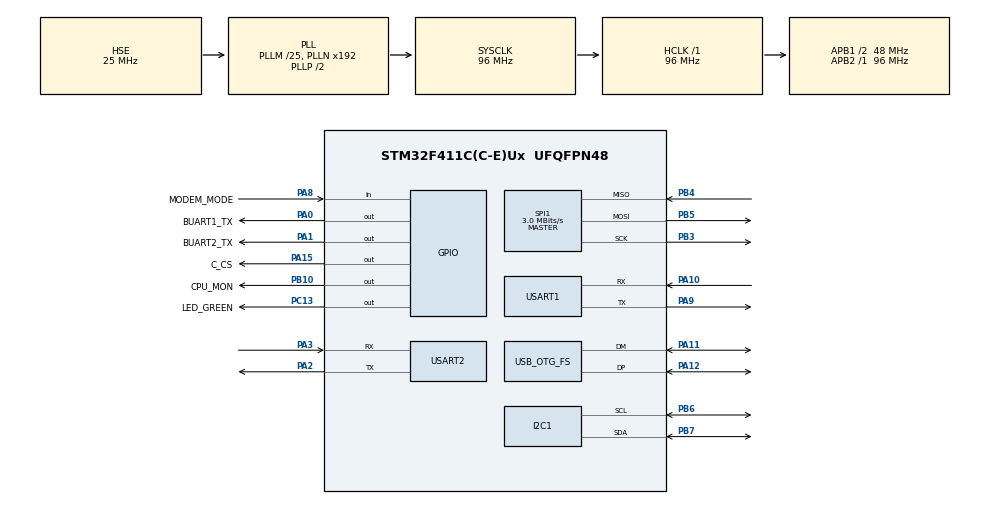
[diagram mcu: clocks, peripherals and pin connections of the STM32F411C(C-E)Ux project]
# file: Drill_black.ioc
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FREERTOS.Queues01=QueueTX,4,HdlcFrame_t,0,Static,QueueTXBuffer,QueueTXControlBlock;QueueRX,4,HdlcFrame_t,0,Static,QueueRXBuffer,QueueRXControlBlock
FREERTOS.Tasks01=defaultTask,24,256,StartDefaultTask,Default,NULL,Static,defaultTaskBuffer,defaultTaskControlBlock;TaskHDLC,48,256,StartTaskHDLC,As weak,NULL,Static,TaskHDLCBuffer,TaskHDLCControlBlock;TaskHK,8,256,StartTaskHK,As weak,NULL,Static,TaskHKBuffer,TaskHKControlBlock
Mcu.Family=STM32F4
Mcu.Name=STM32F411C(C-E)Ux
Mcu.Package=UFQFPN48
NVIC.OTG_FS_IRQn=true\:5\:0\:false\:false\:true\:true\:false\:true\:true
NVIC.PriorityGroup=NVIC_PRIORITYGROUP_4
NVIC.TIM2_IRQn=true\:5\:0\:false\:false\:true\:true\:true\:true\:true
NVIC.TIM3_IRQn=true\:5\:0\:false\:false\:true\:true\:true\:true\:true
NVIC.TIM5_IRQn=true\:15\:0\:false\:false\:true\:false\:false\:true\:true
NVIC.TimeBase=TIM5_IRQn
NVIC.TimeBaseIP=TIM5
PA0-WKUP.GPIO_Label=BUART1_TX
PA0-WKUP.Signal=GPIO_Output
PA1.GPIO_Label=BUART2_TX
PA1.Signal=GPIO_Output
PA10.Mode=Asynchronous
PA10.Signal=USART1_RX
PA11.Mode=Host_Only
PA11.Signal=USB_OTG_FS_DM
PA12.Mode=Host_Only
PA12.Signal=USB_OTG_FS_DP
PA13.Mode=Serial_Wire
PA13.Signal=SYS_JTMS-SWDIO
PA14.Mode=Serial_Wire
PA14.Signal=SYS_JTCK-SWCLK
PA15.GPIO_Label=C_CS
PA15.Signal=GPIO_Output
PA2.Mode=Asynchronous
PA2.Signal=USART2_TX
PA3.Mode=Asynchronous
PA3.Signal=USART2_RX
PA8.GPIO_Label=MODEM_MODE
PA8.GPIO_PuPd=GPIO_PULLUP
PA8.Signal=GPIO_Input
PA9.Mode=Asynchronous
PA9.Signal=USART1_TX
PB10.GPIO_Label=CPU_MON
PB10.Signal=GPIO_Output
PB3.Mode=Full_Duplex_Master
PB3.Signal=SPI1_SCK
PB4.Mode=Full_Duplex_Master
PB4.Signal=SPI1_MISO
PB5.Mode=Full_Duplex_Master
PB5.Signal=SPI1_MOSI
PB6.Mode=I2C
PB6.Signal=I2C1_SCL
PB7.Mode=I2C
PB7.Signal=I2C1_SDA
PC13-ANTI_TAMP.GPIO_Label=LED_GREEN
PC13-ANTI_TAMP.Signal=GPIO_Output
PC14-OSC32_IN.Mode=LSE-External-Oscillator
PC14-OSC32_IN.Signal=RCC_OSC32_IN
PC15-OSC32_OUT.Mode=LSE-External-Oscillator
PC15-OSC32_OUT.Signal=RCC_OSC32_OUT
PH0\ -\ OSC_IN.Mode=HSE-External-Oscillator
PH0\ -\ OSC_IN.Signal=RCC_OSC_IN
PH1\ -\ OSC_OUT.Mode=HSE-External-Oscillator
PH1\ -\ OSC_OUT.Signal=RCC_OSC_OUT
ProjectManager.HeapSize=0x400
ProjectManager.StackSize=0x400
ProjectManager.TargetToolchain=CMake
RCC.48MHZClocksFreq_Value=48000000
RCC.AHBFreq_Value=96000000
RCC.APB1CLKDivider=RCC_HCLK_DIV2
RCC.APB1Freq_Value=48000000
RCC.APB1TimFreq_Value=96000000
RCC.APB2Freq_Value=96000000
RCC.APB2TimFreq_Value=96000000
RCC.CortexFreq_Value=96000000
RCC.HCLKFreq_Value=96000000
RCC.HSE_VALUE=25000000
RCC.HSI_VALUE=16000000
RCC.PLLM=25
RCC.RCC_RTC_Clock_Source=RCC_RTCCLKSOURCE_LSE
RCC.RCC_RTC_Clock_SourceVirtual=RCC_RTCCLKSOURCE_LSE
RCC.SYSCLKFreq_VALUE=96000000
RCC.SYSCLKSource=RCC_SYSCLKSOURCE_PLLCLK
RCC.VCOOutputFreq_Value=192000000
RTC.Month=RTC_MONTH_NOVEMBER
RTC.Year=27
SPI1.BaudRatePrescaler=SPI_BAUDRATEPRESCALER_32
SPI1.CalculateBaudRate=3.0 MBits/s
SPI1.Direction=SPI_DIRECTION_2LINES
SPI1.Mode=SPI_MODE_MASTER
SPI1.VirtualType=VM_MASTER
TIM2.AutoReloadPreload=TIM_AUTORELOAD_PRELOAD_ENABLE
TIM2.Period=132
TIM2.Prescaler=99
TIM3.AutoReloadPreload=TIM_AUTORELOAD_PRELOAD_ENABLE
TIM3.Period=79
TIM3.Prescaler=999
USART1.VirtualMode=VM_ASYNC
USART2.VirtualMode=VM_ASYNC
USB_HOST.SW_VBUS_DRIVE_CDC_FS=true
USB_HOST.USBH_HandleTypeDef=hUsbHostFS
USB_HOST.VirtualModeFS=Cdc
USB_OTG_FS.VirtualMode=Host_Only
USB_OTG_FS.phy_itface=HCD_PHY_EMBEDDED
VP_FREERTOS_VS_CMSIS_V2.Mode=CMSIS_V2
VP_RTC_VS_RTC_Activate.Mode=RTC_Enabled
VP_RTC_VS_RTC_Calendar.Mode=RTC_Calendar
VP_SYS_VS_tim5.Mode=TIM5
VP_TIM2_VS_ClockSourceINT.Mode=Internal
VP_TIM3_VS_ClockSourceINT.Mode=Internal
VP_USB_HOST_VS_USB_HOST_CDC_FS.Mode=CDC_FS
board=custom

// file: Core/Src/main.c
/* USER CODE BEGIN Header */
/**
  ******************************************************************************
  * @file           : main.c
  * @brief          : Main program body
  ******************************************************************************
  * @attention
  *
  * Copyright (c) 2026 STMicroelectronics.
  * All rights reserved.
  *
  * This software is licensed under terms that can be found in the LICENSE file
  * in the root directory of this software component.
  * If no LICENSE file comes with this software, it is provided AS-IS.
  *
  ******************************************************************************
  */
/* USER CODE END Header */
#include "main.h"
#include "cmsis_os.h"
#include "usb_host.h"

/* USER CODE BEGIN Includes */
#include "rtt_term.h"
#include "TaskHDLC.h"

/* USER CODE END Includes */

typedef StaticTask_t osStaticThreadDef_t;
typedef StaticQueue_t osStaticMessageQDef_t;

I2C_HandleTypeDef hi2c1;

RTC_HandleTypeDef hrtc;

SPI_HandleTypeDef hspi1;

TIM_HandleTypeDef htim2;
TIM_HandleTypeDef htim3;

UART_HandleTypeDef huart1;
UART_HandleTypeDef huart2;

/* Definitions for defaultTask */
osThreadId_t defaultTaskHandle;
uint32_t defaultTaskBuffer[ 256 ];
osStaticThreadDef_t defaultTaskControlBlock;
const osThreadAttr_t defaultTask_attributes = {
  .name = "defaultTask",
  .cb_mem = &defaultTaskControlBlock,
  .cb_size = sizeof(defaultTaskControlBlock),
  .stack_mem = &defaultTaskBuffer[0],
  .stack_size = sizeof(defaultTaskBuffer),
  .priority = (osPriority_t) osPriorityNormal,
};
/* Definitions for TaskHDLC */
osThreadId_t TaskHDLCHandle;
uint32_t TaskHDLCBuffer[ 256 ];
osStaticThreadDef_t TaskHDLCControlBlock;
const osThreadAttr_t TaskHDLC_attributes = {
  .name = "TaskHDLC",
  .cb_mem = &TaskHDLCControlBlock,
  .cb_size = sizeof(TaskHDLCControlBlock),
  .stack_mem = &TaskHDLCBuffer[0],
  .stack_size = sizeof(TaskHDLCBuffer),
  .priority = (osPriority_t) osPriorityRealtime,
};
/* Definitions for TaskHK */
osThreadId_t TaskHKHandle;
uint32_t TaskHKBuffer[ 256 ];
osStaticThreadDef_t TaskHKControlBlock;
const osThreadAttr_t TaskHK_attributes = {
  .name = "TaskHK",
  .cb_mem = &TaskHKControlBlock,
  .cb_size = sizeof(TaskHKControlBlock),
  .stack_mem = &TaskHKBuffer[0],
  .stack_size = sizeof(TaskHKBuffer),
  .priority = (osPriority_t) osPriorityLow,
};
/* Definitions for QueueTX */
osMessageQueueId_t QueueTXHandle;
uint8_t QueueTXBuffer[ 4 * sizeof( HdlcFrame_t ) ];
osStaticMessageQDef_t QueueTXControlBlock;
const osMessageQueueAttr_t QueueTX_attributes = {
  .name = "QueueTX",
  .cb_mem = &QueueTXControlBlock,
  .cb_size = sizeof(QueueTXControlBlock),
  .mq_mem = &QueueTXBuffer,
  .mq_size = sizeof(QueueTXBuffer)
};
/* Definitions for QueueRX */
osMessageQueueId_t QueueRXHandle;
uint8_t QueueRXBuffer[ 4 * sizeof( HdlcFrame_t ) ];
osStaticMessageQDef_t QueueRXControlBlock;
const osMessageQueueAttr_t QueueRX_attributes = {
  .name = "QueueRX",
  .cb_mem = &QueueRXControlBlock,
  .cb_size = sizeof(QueueRXControlBlock),
  .mq_mem = &QueueRXBuffer,
  .mq_size = sizeof(QueueRXBuffer)
};
/* USER CODE BEGIN PV */
int Is_gse = 0;   /* MODEM_MODE(PA8) が 0(GND) のとき 1 */

/* USER CODE END PV */

void SystemClock_Config(void);
static void MX_GPIO_Init(void);
static void MX_I2C1_Init(void);
static void MX_RTC_Init(void);
static void MX_SPI1_Init(void);
static void MX_USART1_UART_Init(void);
static void MX_USART2_UART_Init(void);
static void MX_TIM2_Init(void);
static void MX_TIM3_Init(void);
void StartDefaultTask(void *argument);
void StartTaskHDLC(void *argument);
void StartTaskHK(void *argument);

int main(void)
{

  /* MCU Configuration--------------------------------------------------------*/

  /* Reset of all peripherals, Initializes the Flash interface and the Systick. */
  HAL_Init();

  /* Configure the system clock */
  SystemClock_Config();

  /* Initialize all configured peripherals */
  MX_GPIO_Init();
  MX_I2C1_Init();
  MX_RTC_Init();
  MX_SPI1_Init();
  MX_USART1_UART_Init();
  MX_USART2_UART_Init();
  MX_TIM2_Init();
  MX_TIM3_Init();
  /* USER CODE BEGIN 2 */
  Is_gse = (HAL_GPIO_ReadPin(MODEM_MODE_GPIO_Port, MODEM_MODE_Pin) == GPIO_PIN_RESET) ? 1 : 0;
  /* TIM2 は StartTaskHDLC() 内で cmx869b_init() 後に開始する */
  /* USER CODE END 2 */

  /* Init scheduler */
  osKernelInitialize();

  /* USER CODE BEGIN RTOS_MUTEX */
  /* add mutexes, ... */
  RTT_TermInit();
  /* USER CODE END RTOS_MUTEX */

  /* Create the queue(s) */
  /* creation of QueueTX */
  QueueTXHandle = osMessageQueueNew (4, sizeof(HdlcFrame_t), &QueueTX_attributes);

  /* creation of QueueRX */
  QueueRXHandle = osMessageQueueNew (4, sizeof(HdlcFrame_t), &QueueRX_attributes);

  /* USER CODE BEGIN RTOS_QUEUES */
  /* add queues, ... */
  hTxQ = (QueueHandle_t)QueueTXHandle;
  hRxQ = (QueueHandle_t)QueueRXHandle;
  /* USER CODE END RTOS_QUEUES */

  /* Create the thread(s) */
  /* creation of defaultTask */
  defaultTaskHandle = osThreadNew(StartDefaultTask, NULL, &defaultTask_attributes);

  /* creation of TaskHDLC */
  TaskHDLCHandle = osThreadNew(StartTaskHDLC, NULL, &TaskHDLC_attributes);

  /* creation of TaskHK */
  TaskHKHandle = osThreadNew(StartTaskHK, NULL, &TaskHK_attributes);

  /* Start scheduler */
  osKernelStart();

  /* We should never get here as control is now taken by the scheduler */

  /* Infinite loop */
  while (1)
  {

  }
}

void SystemClock_Config(void)
{
  RCC_OscInitTypeDef RCC_OscInitStruct = {0};
  RCC_ClkInitTypeDef RCC_ClkInitStruct = {0};

  /** Configure the main internal regulator output voltage
  */
  __HAL_RCC_PWR_CLK_ENABLE();
  __HAL_PWR_VOLTAGESCALING_CONFIG(PWR_REGULATOR_VOLTAGE_SCALE1);

  /** Initializes the RCC Oscillators according to the specified parameters
  * in the RCC_OscInitTypeDef structure.
  */
  RCC_OscInitStruct.OscillatorType = RCC_OSCILLATORTYPE_HSE|RCC_OSCILLATORTYPE_LSE;
  RCC_OscInitStruct.HSEState = RCC_HSE_ON;
  RCC_OscInitStruct.LSEState = RCC_LSE_ON;
  RCC_OscInitStruct.PLL.PLLState = RCC_PLL_ON;
  RCC_OscInitStruct.PLL.PLLSource = RCC_PLLSOURCE_HSE;
  RCC_OscInitStruct.PLL.PLLM = 25;
  RCC_OscInitStruct.PLL.PLLN = 192;
  RCC_OscInitStruct.PLL.PLLP = RCC_PLLP_DIV2;
  RCC_OscInitStruct.PLL.PLLQ = 4;
  if (HAL_RCC_OscConfig(&RCC_OscInitStruct) != HAL_OK)
  {
    Error_Handler();
  }

  /** Initializes the CPU, AHB and APB buses clocks
  */
  RCC_ClkInitStruct.ClockType = RCC_CLOCKTYPE_HCLK|RCC_CLOCKTYPE_SYSCLK
                              |RCC_CLOCKTYPE_PCLK1|RCC_CLOCKTYPE_PCLK2;
  RCC_ClkInitStruct.SYSCLKSource = RCC_SYSCLKSOURCE_PLLCLK;
  RCC_ClkInitStruct.AHBCLKDivider = RCC_SYSCLK_DIV1;
  RCC_ClkInitStruct.APB1CLKDivider = RCC_HCLK_DIV2;
  RCC_ClkInitStruct.APB2CLKDivider = RCC_HCLK_DIV1;

  if (HAL_RCC_ClockConfig(&RCC_ClkInitStruct, FLASH_LATENCY_3) != HAL_OK)
  {
    Error_Handler();
  }
}

static void MX_I2C1_Init(void)
{

  hi2c1.Instance = I2C1;
  hi2c1.Init.ClockSpeed = 100000;
  hi2c1.Init.DutyCycle = I2C_DUTYCYCLE_2;
  hi2c1.Init.OwnAddress1 = 0;
  hi2c1.Init.AddressingMode = I2C_ADDRESSINGMODE_7BIT;
  hi2c1.Init.DualAddressMode = I2C_DUALADDRESS_DISABLE;
  hi2c1.Init.OwnAddress2 = 0;
  hi2c1.Init.GeneralCallMode = I2C_GENERALCALL_DISABLE;
  hi2c1.Init.NoStretchMode = I2C_NOSTRETCH_DISABLE;
  if (HAL_I2C_Init(&hi2c1) != HAL_OK)
  {
    Error_Handler();
  }

}

static void MX_RTC_Init(void)
{

  RTC_TimeTypeDef sTime = {0};
  RTC_DateTypeDef sDate = {0};

  /** Initialize RTC Only
  */
  hrtc.Instance = RTC;
  hrtc.Init.HourFormat = RTC_HOURFORMAT_24;
  hrtc.Init.AsynchPrediv = 127;
  hrtc.Init.SynchPrediv = 255;
  hrtc.Init.OutPut = RTC_OUTPUT_DISABLE;
  hrtc.Init.OutPutPolarity = RTC_OUTPUT_POLARITY_HIGH;
  hrtc.Init.OutPutType = RTC_OUTPUT_TYPE_OPENDRAIN;
  if (HAL_RTC_Init(&hrtc) != HAL_OK)
  {
    Error_Handler();
  }

  /** Initialize RTC and set the Time and Date
  */
  sTime.Hours = 0x0;
  sTime.Minutes = 0x0;
  sTime.Seconds = 0x0;
  sTime.DayLightSaving = RTC_DAYLIGHTSAVING_NONE;
  sTime.StoreOperation = RTC_STOREOPERATION_RESET;
  if (HAL_RTC_SetTime(&hrtc, &sTime, RTC_FORMAT_BCD) != HAL_OK)
  {
    Error_Handler();
  }
  sDate.WeekDay = RTC_WEEKDAY_MONDAY;
  sDate.Month = RTC_MONTH_NOVEMBER;
  sDate.Date = 0x1;
  sDate.Year = 0x27;

  if (HAL_RTC_SetDate(&hrtc, &sDate, RTC_FORMAT_BCD) != HAL_OK)
  {
    Error_Handler();
  }

}

static void MX_SPI1_Init(void)
{

  /* SPI1 parameter configuration*/
  hspi1.Instance = SPI1;
  hspi1.Init.Mode = SPI_MODE_MASTER;
  hspi1.Init.Direction = SPI_DIRECTION_2LINES;
  hspi1.Init.DataSize = SPI_DATASIZE_8BIT;
  hspi1.Init.CLKPolarity = SPI_POLARITY_LOW;
  hspi1.Init.CLKPhase = SPI_PHASE_1EDGE;
  hspi1.Init.NSS = SPI_NSS_SOFT;
  hspi1.Init.BaudRatePrescaler = SPI_BAUDRATEPRESCALER_32;
  hspi1.Init.FirstBit = SPI_FIRSTBIT_MSB;
  hspi1.Init.TIMode = SPI_TIMODE_DISABLE;
  hspi1.Init.CRCCalculation = SPI_CRCCALCULATION_DISABLE;
  hspi1.Init.CRCPolynomial = 10;
  if (HAL_SPI_Init(&hspi1) != HAL_OK)
  {
    Error_Handler();
  }

}

static void MX_TIM2_Init(void)
{

  TIM_ClockConfigTypeDef sClockSourceConfig = {0};
  TIM_MasterConfigTypeDef sMasterConfig = {0};

  htim2.Instance = TIM2;
  htim2.Init.Prescaler = 99;
  htim2.Init.CounterMode = TIM_COUNTERMODE_UP;
  htim2.Init.Period = 132;
  htim2.Init.ClockDivision = TIM_CLOCKDIVISION_DIV1;
  htim2.Init.AutoReloadPreload = TIM_AUTORELOAD_PRELOAD_ENABLE;
  if (HAL_TIM_Base_Init(&htim2) != HAL_OK)
  {
    Error_Handler();
  }
  sClockSourceConfig.ClockSource = TIM_CLOCKSOURCE_INTERNAL;
  if (HAL_TIM_ConfigClockSource(&htim2, &sClockSourceConfig) != HAL_OK)
  {
    Error_Handler();
  }
  sMasterConfig.MasterOutputTrigger = TIM_TRGO_RESET;
  sMasterConfig.MasterSlaveMode = TIM_MASTERSLAVEMODE_DISABLE;
  if (HAL_TIMEx_MasterConfigSynchronization(&htim2, &sMasterConfig) != HAL_OK)
  {
    Error_Handler();
  }

}

static void MX_TIM3_Init(void)
{

  TIM_ClockConfigTypeDef sClockSourceConfig = {0};
  TIM_MasterConfigTypeDef sMasterConfig = {0};

  htim3.Instance = TIM3;
  htim3.Init.Prescaler = 999;
  htim3.Init.CounterMode = TIM_COUNTERMODE_UP;
  htim3.Init.Period = 79;
  htim3.Init.ClockDivision = TIM_CLOCKDIVISION_DIV1;
  htim3.Init.AutoReloadPreload = TIM_AUTORELOAD_PRELOAD_ENABLE;
  if (HAL_TIM_Base_Init(&htim3) != HAL_OK)
  {
    Error_Handler();
  }
  sClockSourceConfig.ClockSource = TIM_CLOCKSOURCE_INTERNAL;
  if (HAL_TIM_ConfigClockSource(&htim3, &sClockSourceConfig) != HAL_OK)
  {
    Error_Handler();
  }
  sMasterConfig.MasterOutputTrigger = TIM_TRGO_RESET;
  sMasterConfig.MasterSlaveMode = TIM_MASTERSLAVEMODE_DISABLE;
  if (HAL_TIMEx_MasterConfigSynchronization(&htim3, &sMasterConfig) != HAL_OK)
  {
    Error_Handler();
  }

}

static void MX_USART1_UART_Init(void)
{

  huart1.Instance = USART1;
  huart1.Init.BaudRate = 115200;
  huart1.Init.WordLength = UART_WORDLENGTH_8B;
  huart1.Init.StopBits = UART_STOPBITS_1;
  huart1.Init.Parity = UART_PARITY_NONE;
  huart1.Init.Mode = UART_MODE_TX_RX;
  huart1.Init.HwFlowCtl = UART_HWCONTROL_NONE;
  huart1.Init.OverSampling = UART_OVERSAMPLING_16;
  if (HAL_UART_Init(&huart1) != HAL_OK)
  {
    Error_Handler();
  }

}

static void MX_USART2_UART_Init(void)
{

  huart2.Instance = USART2;
  huart2.Init.BaudRate = 115200;
  huart2.Init.WordLength = UART_WORDLENGTH_8B;
  huart2.Init.StopBits = UART_STOPBITS_1;
  huart2.Init.Parity = UART_PARITY_NONE;
  huart2.Init.Mode = UART_MODE_TX_RX;
  huart2.Init.HwFlowCtl = UART_HWCONTROL_NONE;
  huart2.Init.OverSampling = UART_OVERSAMPLING_16;
  if (HAL_UART_Init(&huart2) != HAL_OK)
  {
    Error_Handler();
  }

}

static void MX_GPIO_Init(void)
{
  GPIO_InitTypeDef GPIO_InitStruct = {0};

  /* GPIO Ports Clock Enable */
  __HAL_RCC_GPIOC_CLK_ENABLE();
  __HAL_RCC_GPIOH_CLK_ENABLE();
  __HAL_RCC_GPIOA_CLK_ENABLE();
  __HAL_RCC_GPIOB_CLK_ENABLE();

  /*Configure GPIO pin Output Level */
  HAL_GPIO_WritePin(LED_GREEN_GPIO_Port, LED_GREEN_Pin, GPIO_PIN_RESET);

  /*Configure GPIO pin Output Level */
  HAL_GPIO_WritePin(GPIOA, BUART1_TX_Pin|BUART2_TX_Pin|C_CS_Pin, GPIO_PIN_RESET);

  /*Configure GPIO pin Output Level */
  HAL_GPIO_WritePin(CPU_MON_GPIO_Port, CPU_MON_Pin, GPIO_PIN_RESET);

  /*Configure GPIO pin : LED_GREEN_Pin */
  GPIO_InitStruct.Pin = LED_GREEN_Pin;
  GPIO_InitStruct.Mode = GPIO_MODE_OUTPUT_PP;
  GPIO_InitStruct.Pull = GPIO_NOPULL;
  GPIO_InitStruct.Speed = GPIO_SPEED_FREQ_LOW;
  HAL_GPIO_Init(LED_GREEN_GPIO_Port, &GPIO_InitStruct);

  /*Configure GPIO pins : BUART1_TX_Pin BUART2_TX_Pin C_CS_Pin */
  GPIO_InitStruct.Pin = BUART1_TX_Pin|BUART2_TX_Pin|C_CS_Pin;
  GPIO_InitStruct.Mode = GPIO_MODE_OUTPUT_PP;
  GPIO_InitStruct.Pull = GPIO_NOPULL;
  GPIO_InitStruct.Speed = GPIO_SPEED_FREQ_LOW;
  HAL_GPIO_Init(GPIOA, &GPIO_InitStruct);

  /*Configure GPIO pin : CPU_MON_Pin */
  GPIO_InitStruct.Pin = CPU_MON_Pin;
  GPIO_InitStruct.Mode = GPIO_MODE_OUTPUT_PP;
  GPIO_InitStruct.Pull = GPIO_NOPULL;
  GPIO_InitStruct.Speed = GPIO_SPEED_FREQ_LOW;
  HAL_GPIO_Init(CPU_MON_GPIO_Port, &GPIO_InitStruct);

  /*Configure GPIO pin : MODEM_MODE_Pin */
  GPIO_InitStruct.Pin = MODEM_MODE_Pin;
  GPIO_InitStruct.Mode = GPIO_MODE_INPUT;
  GPIO_InitStruct.Pull = GPIO_PULLUP;
  HAL_GPIO_Init(MODEM_MODE_GPIO_Port, &GPIO_InitStruct);

}

void StartDefaultTask(void *argument)
{
  /* init code for USB_HOST */
  MX_USB_HOST_Init();
  for(;;)
  {
    osDelay(1);
  }
}

__weak void StartTaskHDLC(void *argument)
{
  for(;;)
  {
    osDelay(1);
  }
}

__weak void StartTaskHK(void *argument)
{
  for(;;)
  {
    osDelay(1);
  }
}

void HAL_TIM_PeriodElapsedCallback(TIM_HandleTypeDef *htim)
{
  if (htim->Instance == TIM5)
  {
    HAL_IncTick();
  }
  /* USER CODE BEGIN Callback 1 */
  if (htim->Instance == TIM2)
  {
    Wakeup_TaskHDLC_FromISR();/* CPU_MON は TaskHDLC 側で処理時間計測に使用 */
  }
  /* USER CODE END Callback 1 */
}

void Error_Handler(void)
{
  __disable_irq();
  while (1)
  {
  }
}
